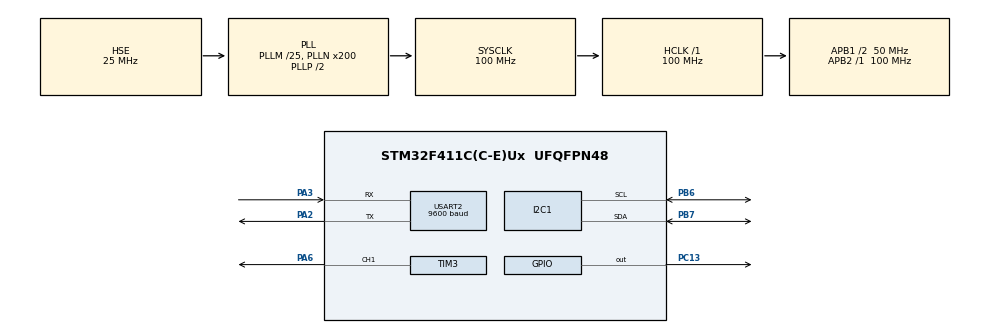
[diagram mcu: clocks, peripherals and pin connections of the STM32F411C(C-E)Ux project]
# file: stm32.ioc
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FREERTOS.Mutexes01=stateMutex,Dynamic,NULL,Available
FREERTOS.Tasks01=SensorActuator,24,256,SensorActuatorTask,Default,NULL,Dynamic,NULL,NULL;System,16,512,SystemTask,Default,NULL,Dynamic,NULL,NULL;Comms,24,256,CommsTask,Default,NULL,Dynamic,NULL,NULL
FREERTOS.configUSE_NEWLIB_REENTRANT=1
I2C1.I2C_Mode=I2C_Fast
Mcu.Family=STM32F4
Mcu.Name=STM32F411C(C-E)Ux
Mcu.Package=UFQFPN48
NVIC.PriorityGroup=NVIC_PRIORITYGROUP_4
NVIC.TIM1_UP_TIM10_IRQn=true\:15\:0\:false\:false\:true\:false\:false\:true\:true
NVIC.TimeBase=TIM1_UP_TIM10_IRQn
NVIC.TimeBaseIP=TIM1
PA13.Mode=Serial_Wire
PA13.Signal=SYS_JTMS-SWDIO
PA14.Mode=Serial_Wire
PA14.Signal=SYS_JTCK-SWCLK
PA2.Mode=Asynchronous
PA2.Signal=USART2_TX
PA3.Mode=Asynchronous
PA3.Signal=USART2_RX
PA6.Signal=S_TIM3_CH1
PB6.Mode=I2C
PB6.Signal=I2C1_SCL
PB7.Mode=I2C
PB7.Signal=I2C1_SDA
PC13-ANTI_TAMP.Signal=GPIO_Output
PH0\ -\ OSC_IN.Mode=HSE-External-Oscillator
PH0\ -\ OSC_IN.Signal=RCC_OSC_IN
PH1\ -\ OSC_OUT.Mode=HSE-External-Oscillator
PH1\ -\ OSC_OUT.Signal=RCC_OSC_OUT
ProjectManager.HeapSize=0x200
ProjectManager.StackSize=0x400
ProjectManager.TargetToolchain=STM32CubeIDE
RCC.48MHZClocksFreq_Value=50000000
RCC.AHBFreq_Value=100000000
RCC.APB1CLKDivider=RCC_HCLK_DIV2
RCC.APB1Freq_Value=50000000
RCC.APB1TimFreq_Value=100000000
RCC.APB2Freq_Value=100000000
RCC.APB2TimFreq_Value=100000000
RCC.CortexFreq_Value=100000000
RCC.HCLKFreq_Value=100000000
RCC.HSE_VALUE=25000000
RCC.HSI_VALUE=16000000
RCC.LSE_VALUE=32768
RCC.PLLM=25
RCC.PLLN=200
RCC.PLLSourceVirtual=RCC_PLLSOURCE_HSE
RCC.SYSCLKFreq_VALUE=100000000
RCC.SYSCLKSource=RCC_SYSCLKSOURCE_PLLCLK
RCC.VCOOutputFreq_Value=200000000
SH.S_TIM3_CH1.0=TIM3_CH1,PWM Generation1 CH1
TIM3.Channel-PWM\ Generation1\ CH1=TIM_CHANNEL_1
TIM3.Period=3999
USART2.BaudRate=9600
USART2.VirtualMode=VM_ASYNC
VP_FREERTOS_VS_CMSIS_V2.Mode=CMSIS_V2
VP_SYS_VS_tim1.Mode=TIM1
VP_TIM3_VS_ClockSourceINT.Mode=Internal
board=custom

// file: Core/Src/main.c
/* USER CODE BEGIN Header */
/**
  ******************************************************************************
  * @file           : main.c
  * @brief          : Main program body
  ******************************************************************************
  * @attention
  *
  * Copyright (c) 2026 STMicroelectronics.
  * All rights reserved.
  *
  * This software is licensed under terms that can be found in the LICENSE file
  * in the root directory of this software component.
  * If no LICENSE file comes with this software, it is provided AS-IS.
  *
  ******************************************************************************
  */
/* USER CODE END Header */
#include "main.h"
#include "cmsis_os.h"

/* USER CODE BEGIN Includes */

#include <string.h>

#include "state/state_manager.h"

#include "tasks/sensor_actuator_task.h"
#include "tasks/system_task.h"
#include "tasks/comms_task.h"

/* USER CODE END Includes */

I2C_HandleTypeDef hi2c1;

TIM_HandleTypeDef htim3;

UART_HandleTypeDef huart2;

/* Definitions for SensorActuator */
osThreadId_t SensorActuatorHandle;
const osThreadAttr_t SensorActuator_attributes = {
  .name = "SensorActuator",
  .stack_size = 256 * 4,
  .priority = (osPriority_t) osPriorityNormal,
};
/* Definitions for System */
osThreadId_t SystemHandle;
const osThreadAttr_t System_attributes = {
  .name = "System",
  .stack_size = 512 * 4,
  .priority = (osPriority_t) osPriorityBelowNormal,
};
/* Definitions for Comms */
osThreadId_t CommsHandle;
const osThreadAttr_t Comms_attributes = {
  .name = "Comms",
  .stack_size = 256 * 4,
  .priority = (osPriority_t) osPriorityNormal,
};
/* Definitions for stateMutex */
osMutexId_t stateMutexHandle;
const osMutexAttr_t stateMutex_attributes = {
  .name = "stateMutex"
};

void SystemClock_Config(void);
static void MX_GPIO_Init(void);
static void MX_I2C1_Init(void);
static void MX_TIM3_Init(void);
static void MX_USART2_UART_Init(void);
void SensorActuatorTask(void *argument);
void SystemTask(void *argument);
void CommsTask(void *argument);

int main(void)
{

  /* MCU Configuration--------------------------------------------------------*/

  /* Reset of all peripherals, Initializes the Flash interface and the Systick. */
  HAL_Init();

  /* Configure the system clock */
  SystemClock_Config();

  /* Initialize all configured peripherals */
  MX_GPIO_Init();
  MX_I2C1_Init();
  MX_TIM3_Init();
  MX_USART2_UART_Init();
  /* USER CODE BEGIN 2 */

  initStateManager();

  /* USER CODE END 2 */

  /* Init scheduler */
  osKernelInitialize();
  /* Create the mutex(es) */
  /* creation of stateMutex */
  stateMutexHandle = osMutexNew(&stateMutex_attributes);

  /* Create the thread(s) */
  /* creation of SensorActuator */
  SensorActuatorHandle = osThreadNew(SensorActuatorTask, NULL, &SensorActuator_attributes);

  /* creation of System */
  SystemHandle = osThreadNew(SystemTask, NULL, &System_attributes);

  /* creation of Comms */
  CommsHandle = osThreadNew(CommsTask, NULL, &Comms_attributes);

  /* Start scheduler */
  osKernelStart();

  /* We should never get here as control is now taken by the scheduler */

  /* Infinite loop */
  while (1)
  {

  }
}

void SystemClock_Config(void)
{
  RCC_OscInitTypeDef RCC_OscInitStruct = {0};
  RCC_ClkInitTypeDef RCC_ClkInitStruct = {0};

  /** Configure the main internal regulator output voltage
  */
  __HAL_RCC_PWR_CLK_ENABLE();
  __HAL_PWR_VOLTAGESCALING_CONFIG(PWR_REGULATOR_VOLTAGE_SCALE1);

  /** Initializes the RCC Oscillators according to the specified parameters
  * in the RCC_OscInitTypeDef structure.
  */
  RCC_OscInitStruct.OscillatorType = RCC_OSCILLATORTYPE_HSE;
  RCC_OscInitStruct.HSEState = RCC_HSE_ON;
  RCC_OscInitStruct.PLL.PLLState = RCC_PLL_ON;
  RCC_OscInitStruct.PLL.PLLSource = RCC_PLLSOURCE_HSE;
  RCC_OscInitStruct.PLL.PLLM = 25;
  RCC_OscInitStruct.PLL.PLLN = 200;
  RCC_OscInitStruct.PLL.PLLP = RCC_PLLP_DIV2;
  RCC_OscInitStruct.PLL.PLLQ = 4;
  if (HAL_RCC_OscConfig(&RCC_OscInitStruct) != HAL_OK)
  {
    Error_Handler();
  }

  /** Initializes the CPU, AHB and APB buses clocks
  */
  RCC_ClkInitStruct.ClockType = RCC_CLOCKTYPE_HCLK|RCC_CLOCKTYPE_SYSCLK
                              |RCC_CLOCKTYPE_PCLK1|RCC_CLOCKTYPE_PCLK2;
  RCC_ClkInitStruct.SYSCLKSource = RCC_SYSCLKSOURCE_PLLCLK;
  RCC_ClkInitStruct.AHBCLKDivider = RCC_SYSCLK_DIV1;
  RCC_ClkInitStruct.APB1CLKDivider = RCC_HCLK_DIV2;
  RCC_ClkInitStruct.APB2CLKDivider = RCC_HCLK_DIV1;

  if (HAL_RCC_ClockConfig(&RCC_ClkInitStruct, FLASH_LATENCY_3) != HAL_OK)
  {
    Error_Handler();
  }
}

static void MX_I2C1_Init(void)
{

  hi2c1.Instance = I2C1;
  hi2c1.Init.ClockSpeed = 400000;
  hi2c1.Init.DutyCycle = I2C_DUTYCYCLE_2;
  hi2c1.Init.OwnAddress1 = 0;
  hi2c1.Init.AddressingMode = I2C_ADDRESSINGMODE_7BIT;
  hi2c1.Init.DualAddressMode = I2C_DUALADDRESS_DISABLE;
  hi2c1.Init.OwnAddress2 = 0;
  hi2c1.Init.GeneralCallMode = I2C_GENERALCALL_DISABLE;
  hi2c1.Init.NoStretchMode = I2C_NOSTRETCH_DISABLE;
  if (HAL_I2C_Init(&hi2c1) != HAL_OK)
  {
    Error_Handler();
  }

}

static void MX_TIM3_Init(void)
{

  TIM_ClockConfigTypeDef sClockSourceConfig = {0};
  TIM_MasterConfigTypeDef sMasterConfig = {0};
  TIM_OC_InitTypeDef sConfigOC = {0};

  htim3.Instance = TIM3;
  htim3.Init.Prescaler = 0;
  htim3.Init.CounterMode = TIM_COUNTERMODE_UP;
  htim3.Init.Period = 3999;
  htim3.Init.ClockDivision = TIM_CLOCKDIVISION_DIV1;
  htim3.Init.AutoReloadPreload = TIM_AUTORELOAD_PRELOAD_DISABLE;
  if (HAL_TIM_Base_Init(&htim3) != HAL_OK)
  {
    Error_Handler();
  }
  sClockSourceConfig.ClockSource = TIM_CLOCKSOURCE_INTERNAL;
  if (HAL_TIM_ConfigClockSource(&htim3, &sClockSourceConfig) != HAL_OK)
  {
    Error_Handler();
  }
  if (HAL_TIM_PWM_Init(&htim3) != HAL_OK)
  {
    Error_Handler();
  }
  sMasterConfig.MasterOutputTrigger = TIM_TRGO_RESET;
  sMasterConfig.MasterSlaveMode = TIM_MASTERSLAVEMODE_DISABLE;
  if (HAL_TIMEx_MasterConfigSynchronization(&htim3, &sMasterConfig) != HAL_OK)
  {
    Error_Handler();
  }
  sConfigOC.OCMode = TIM_OCMODE_PWM1;
  sConfigOC.Pulse = 0;
  sConfigOC.OCPolarity = TIM_OCPOLARITY_HIGH;
  sConfigOC.OCFastMode = TIM_OCFAST_DISABLE;
  if (HAL_TIM_PWM_ConfigChannel(&htim3, &sConfigOC, TIM_CHANNEL_1) != HAL_OK)
  {
    Error_Handler();
  }
  HAL_TIM_MspPostInit(&htim3);

}

static void MX_USART2_UART_Init(void)
{

  huart2.Instance = USART2;
  huart2.Init.BaudRate = 9600;
  huart2.Init.WordLength = UART_WORDLENGTH_8B;
  huart2.Init.StopBits = UART_STOPBITS_1;
  huart2.Init.Parity = UART_PARITY_NONE;
  huart2.Init.Mode = UART_MODE_TX_RX;
  huart2.Init.HwFlowCtl = UART_HWCONTROL_NONE;
  huart2.Init.OverSampling = UART_OVERSAMPLING_16;
  if (HAL_UART_Init(&huart2) != HAL_OK)
  {
    Error_Handler();
  }

}

static void MX_GPIO_Init(void)
{
  GPIO_InitTypeDef GPIO_InitStruct = {0};

  /* GPIO Ports Clock Enable */
  __HAL_RCC_GPIOC_CLK_ENABLE();
  __HAL_RCC_GPIOH_CLK_ENABLE();
  __HAL_RCC_GPIOA_CLK_ENABLE();
  __HAL_RCC_GPIOB_CLK_ENABLE();

  /*Configure GPIO pin Output Level */
  HAL_GPIO_WritePin(GPIOC, GPIO_PIN_13, GPIO_PIN_RESET);

  /*Configure GPIO pin : PC13 */
  GPIO_InitStruct.Pin = GPIO_PIN_13;
  GPIO_InitStruct.Mode = GPIO_MODE_OUTPUT_PP;
  GPIO_InitStruct.Pull = GPIO_NOPULL;
  GPIO_InitStruct.Speed = GPIO_SPEED_FREQ_LOW;
  HAL_GPIO_Init(GPIOC, &GPIO_InitStruct);

}

void SensorActuatorTask(void *argument)
{
  /* USER CODE BEGIN 5 */
  SensorActuatorTaskImpl(argument);
  /* USER CODE END 5 */
}

void SystemTask(void *argument)
{
  /* USER CODE BEGIN SystemTask */
  SystemTaskImpl(argument);
  /* USER CODE END SystemTask */
}

void CommsTask(void *argument)
{
  /* USER CODE BEGIN CommsTask */
  CommsTaskImpl(argument);
  /* USER CODE END CommsTask */
}

void HAL_TIM_PeriodElapsedCallback(TIM_HandleTypeDef *htim)
{
  if (htim->Instance == TIM1)
  {
    HAL_IncTick();
  }
}

void Error_Handler(void)
{
  __disable_irq();
  while (1)
  {
  }
}
